# R7FA2A2AD register map
Vendor: Renesas Electronics Corporation; Series: RA2A2; File version: 1.30.00
CPU: CM23 r1p0, little endian, MPU, no FPU, VTOR, 2 interrupt priority bits, 32 interrupts
Registers are 8-bit, read-write, reset 0x0 unless marked. A register's access mark holds for its fields unless they carry their own. Offsets are from the block's base; [hi:lo] are bit positions; 'fields as' and 'values as' point back to an identical list.

## MMF — Memory Mirror Function
Base 0x40001000
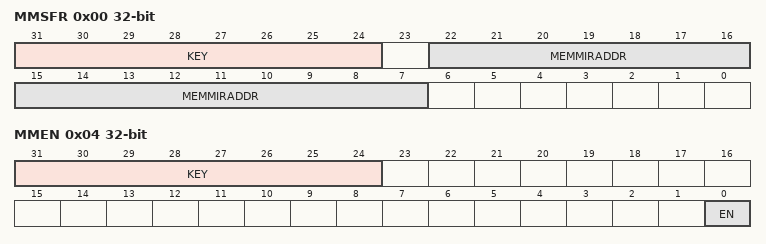
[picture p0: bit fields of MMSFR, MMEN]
0x00 MMSFR 32-bit — MemMirror Special Function Register
  [31:24] KEY wo — MMSFR Key Code
  [22:7] MEMMIRADDR — Memory Mirror Address
0x04 MMEN 32-bit — MemMirror Enable Register
  [31:24] KEY wo — MMEN Key Code
  [0] EN — Memory Mirror Function Enable
    0=Disable MMF; 1=Enable MMF

## SRAM — SRAM Control
Base 0x40002000
0x00 PARIOAD — SRAM Parity Error Operation After Detection Register
  [0] OAD — Operation After Detection
    0=Non-maskable interrupt; 1=Reset
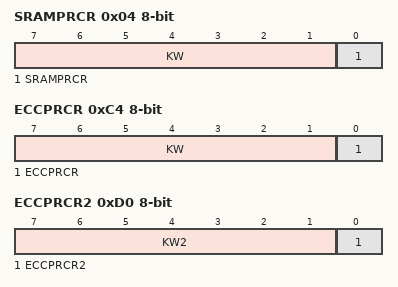
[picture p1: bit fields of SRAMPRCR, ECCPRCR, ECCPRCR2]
0x04 SRAMPRCR — SRAM Protection Register
  [7:1] KW wo — Write Key Code
  [0] SRAMPRCR — Register Write Control
    0=Disable writes to protected registers; 1=Enable writes to protected registers
0xC0 ECCMODE — ECC Operating Mode Control Register
  [1:0] ECCMOD — ECC Operating Mode Select
    0=Disable ECC function; 1=Setting prohibited; 2=Enable ECC function without error checking; 3=Enable ECC function with error checking
0xC1 ECC2STS — ECC 2-Bit Error Status Register
  [0] ECC2ERR — ECC 2-Bit Error Status
    0=No 2-bit ECC error occurred; 1=2-bit ECC error occurred
0xC2 ECC1STSEN — ECC 1-Bit Error Information Update Enable Register
  [0] E1STSEN — ECC 1-Bit Error Information Update Enable
    0=Disable updating of 1-bit ECC error information; 1=Enable updating of 1-bit ECC error information
0xC3 ECC1STS — ECC 1-Bit Error Status Register
  [0] ECC1ERR — ECC 1-Bit Error Status
    0=No 1-bit ECC error occurred; 1=1-bit ECC error occurred
0xC4 ECCPRCR — ECC Protection Register
  [7:1] KW wo — Write Key Code
    120=Enable write to the ECCPRCR bit; other=Others (Disable write to the ECCPRCR bit)
  [0] ECCPRCR — Register Write Control
    0=Disable writes to the protected registers; 1=Enable writes to the protected registers
0xD0 ECCPRCR2 — ECC Protection Register 2
  [7:1] KW2 wo — Write Key Code
    120=Enable write to the ECCPRCR2 bit; other=Others (Disable write to the ECCPRCR2 bit)
  [0] ECCPRCR2 — Register Write Control
    values as ECCPRCR.ECCPRCR
0xD4 ECCETST — ECC Test Control Register
  [0] TSTBYP — ECC Bypass Select
    0=Disable ECC bypass; 1=Enable ECC bypass
0xD8 ECCOAD — SRAM ECC Error Operation After Detection Register
  fields as PARIOAD

## BUS — BUS Control
Base 0x40003000
0x1008 BUSMCNTSYS 16-bit — Master Bus Control Register SYS
  [15] IERES — Ignore Error Responses
    0=A bus error is reported; 1=A bus error is not reported
0x100C BUSMCNTDMA 16-bit — Master Bus Control Register DMA
  fields as BUSMCNTSYS
0x1820 BUS3ERRADD 32-bit ro reset not defined — Bus Error Address Register 3
  [31:0] BERAD — Bus Error Address
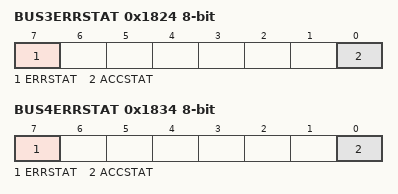
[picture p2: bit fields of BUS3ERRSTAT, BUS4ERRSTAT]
0x1824 BUS3ERRSTAT ro (reset mask 0xFE) — BUS Error Status Register 3
  [7] ERRSTAT — Bus Error Status flag
    0=No bus error occurred; 1=Bus error occurred
  [0] ACCSTAT — Error Access Status flag
    0=Read access; 1=Write access
0x1830 BUS4ERRADD 32-bit ro reset not defined — Bus Error Address Register 4
  [31:0] BERAD — Bus Error Address
0x1834 BUS4ERRSTAT ro (reset mask 0xFE) — BUS Error Status Register 4
  fields as BUS3ERRSTAT

## DTC — Data Transfer Controller
Base 0x40005400
0x00 DTCCR reset 0x8 — DTC Control Register
  [4] RRS — DTC Transfer Information Read Skip Enable
    0=Transfer information read is not skipped; 1=Transfer information read is skipped when vector numbers match
0x04 DTCVBR 32-bit — DTC Vector Base Register
0x0C DTCST — DTC Module Start Register
  [0] DTCST — DTC Module Start
    0=DTC module stopped; 1=DTC module started
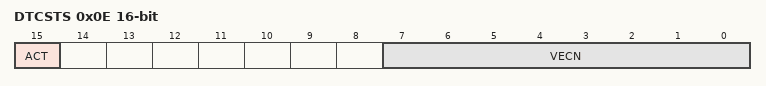
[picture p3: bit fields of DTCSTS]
0x0E DTCSTS 16-bit ro — DTC Status Register
  [15] ACT — DTC Active Flag
    0=DTC transfer operation is not in progress; 1=DTC transfer operation is in progress
  [7:0] VECN — DTC-Activating Vector Number Monitoring

## Notices in the file
This software is supplied by Renesas Electronics Corporation and is only intended for
use with Renesas products. No other uses are authorized. This software is owned by
Renesas Electronics Corporation and is protected under all applicable laws, including
copyright laws.
THIS SOFTWARE IS PROVIDED "AS IS" AND RENESAS MAKES NO WARRANTIES REGARDING
THIS SOFTWARE, WHETHER EXPRESS, IMPLIED OR STATUTORY, INCLUDING BUT NOT LIMITED TO
WARRANTIES OF MERCHANTABILITY, FITNESS FOR A PARTICULAR PURPOSE AND NON-INFRINGEMENT.
ALL SUCH WARRANTIES ARE EXPRESSLY DISCLAIMED. TO THE MAXIMUM EXTENT PERMITTED NOT
PROHIBITED BY LAW, NEITHER RENESAS ELECTRONICS CORPORATION NOR ANY OF ITS AFFILIATED
COMPANIES SHALL BE LIABLE FOR ANY DIRECT, INDIRECT, SPECIAL, INCIDENTAL OR CONSEQUENTIAL
DAMAGES FOR ANY REASON RELATED TO THIS SOFTWARE, EVEN IF RENESAS OR ITS AFFILIATES HAVE
BEEN ADVISED OF THE POSSIBILITY OF SUCH DAMAGES.
Renesas reserves the right, without notice, to make changes to this software and to
discontinue the availability of this software. By using this software, you agree to
the additional terms and conditions found by accessing the following link:
http://www.renesas.com/disclaimer
